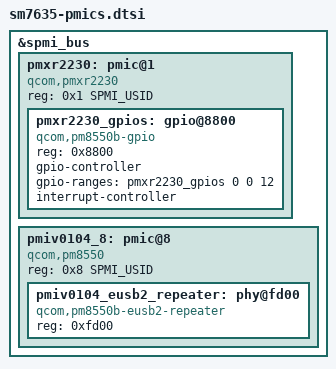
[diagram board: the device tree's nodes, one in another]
// SPDX-License-Identifier: BSD-3-Clause
/*
 * Copyright (c) 2025, Danila Tikhonov <danila@jiaxyga.com>
 */

/ {

};

&spmi_bus {
	pmxr2230: pmic@1 {
		compatible = "qcom,pmxr2230", "qcom,spmi-pmic";
		reg = <0x1 SPMI_USID>;
		#address-cells = <1>;
		#size-cells = <0>;

		pmxr2230_gpios: gpio@8800 {
			compatible = "qcom,pm8550b-gpio", "qcom,spmi-gpio";
			reg = <0x8800>;
			gpio-controller;
			gpio-ranges = <&pmxr2230_gpios 0 0 12>;
			#gpio-cells = <2>;
			interrupt-controller;
			#interrupt-cells = <2>;
		};
	};

	pmiv0104_8: pmic@8 {
		compatible = "qcom,pm8550", "qcom,spmi-pmic";
		reg = <0x8 SPMI_USID>;
		#address-cells = <1>;
		#size-cells = <0>;

		pmiv0104_eusb2_repeater: phy@fd00 {
			compatible = "qcom,pm8550b-eusb2-repeater";
			reg = <0xfd00>;
			#phy-cells = <0>;
		};
	};
};
